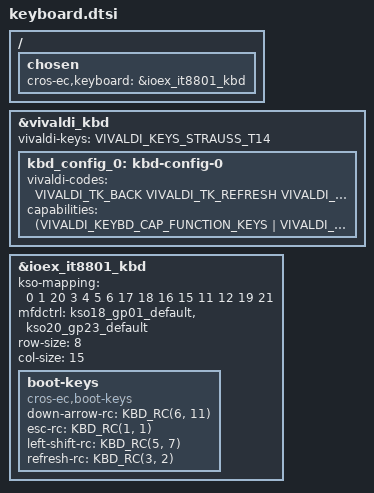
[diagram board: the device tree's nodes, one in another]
/* Copyright 2025 The ChromiumOS Authors
 * Use of this source code is governed by a BSD-style license that can be
 * found in the LICENSE file.
 */

/{
	chosen {
		cros-ec,keyboard = &ioex_it8801_kbd;
	};
};

&vivaldi_kbd {
	vivaldi-keys = <VIVALDI_KEYS_STRAUSS_T14>;

	kbd_config_0: kbd-config-0 {
		vivaldi-codes = <
			VIVALDI_TK_BACK               /* T1 */
			VIVALDI_TK_REFRESH            /* T2 */
			VIVALDI_TK_FULLSCREEN         /* T3 */
			VIVALDI_TK_OVERVIEW           /* T4 */
			VIVALDI_TK_SNAPSHOT           /* T5 */
			VIVALDI_TK_BRIGHTNESS_DOWN    /* T6 */
			VIVALDI_TK_BRIGHTNESS_UP      /* T7 */
			VIVALDI_TK_DICTATE            /* T8 */
			VIVALDI_TK_ACCESSIBILITY      /* T9 */
			VIVALDI_TK_PLAY_PAUSE         /* T10 */
			VIVALDI_TK_MICMUTE            /* T11 */
			VIVALDI_TK_VOL_MUTE           /* T12 */
			VIVALDI_TK_VOL_DOWN           /* T13 */
			VIVALDI_TK_VOL_UP             /* T14 */
		>;
		capabilities = <
			(VIVALDI_KEYBD_CAP_FUNCTION_KEYS |
			 VIVALDI_KEYBD_CAP_ASSISTANT_KEY)
		>;
	};
};

&ioex_it8801_kbd {
          status="okay";
          kso-mapping = <0 1 20 3 4 5 6 17 18 16 15 11 12 19 21>;
          mfdctrl = <&kso18_gp01_default &kso20_gp23_default>;
          row-size = <8>;
          col-size = <15>;
};

&ioex_it8801_kbd {
	boot-keys {
		compatible = "cros-ec,boot-keys";
		down-arrow-rc = <KBD_RC(6, 11)>;
		esc-rc = <KBD_RC(1, 1)>;
		left-shift-rc = <KBD_RC(5, 7)>;
		refresh-rc = <KBD_RC(3, 2)>;
	};
};
